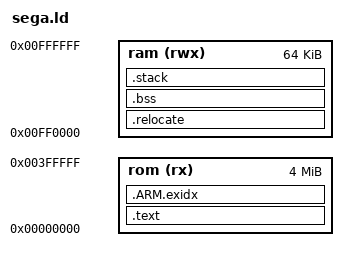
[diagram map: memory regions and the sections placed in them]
/*
 * Sega Genesis Base Project
 *
 * Copyright (c) 2023 Neil Klingensmith
 * neil@cs.luc.edu
 *
 *
 * Permission is hereby granted, free of charge, to any person obtaining a copy
 * of this software and associated documentation files (the "Software"), to deal
 * in the Software without restriction, including without limitation the rights
 * to use, copy, modify, merge, publish, distribute, sublicense, and/or sell
 * copies of the Software, and to permit persons to whom the Software is
 * furnished to do so, subject to the following conditions:
 * 
 * The above copyright notice and this permission notice shall be included in all
 * copies or substantial portions of the Software.
 * 
 * THE SOFTWARE IS PROVIDED "AS IS", WITHOUT WARRANTY OF ANY KIND, EXPRESS OR
 * IMPLIED, INCLUDING BUT NOT LIMITED TO THE WARRANTIES OF MERCHANTABILITY,
 * FITNESS FOR A PARTICULAR PURPOSE AND NONINFRINGEMENT. IN NO EVENT SHALL THE
 * AUTHORS OR COPYRIGHT HOLDERS BE LIABLE FOR ANY CLAIM, DAMAGES OR OTHER
 * LIABILITY, WHETHER IN AN ACTION OF CONTRACT, TORT OR OTHERWISE, ARISING FROM,
 * OUT OF OR IN CONNECTION WITH THE SOFTWARE OR THE USE OR OTHER DEALINGS IN THE
 * SOFTWARE.
 *
 */

STACK_SIZE = DEFINED(STACK_SIZE) ? STACK_SIZE : DEFINED(__stack_size__) ? __stack_size__ : 0x800;

/* Memory Spaces Definitions */
MEMORY
{
  rom      (rx)  : ORIGIN = 0x000000, LENGTH = 0x400000
  ram      (rwx) : ORIGIN = 0xFF0000, LENGTH = 0x010000
}

/* Section Definitions */
SECTIONS
{
    .text :
    {
        . = ALIGN(4);
        _sfixed = .;
        KEEP(*(.vectors .vectors.*))
	KEEP(*(.romheader))
        *(.text .text.* .gnu.linkonce.t.*)
        *(.glue_7t) *(.glue_7)
        *(.rodata .rodata* .gnu.linkonce.r.*)
        *(.ARM.extab* .gnu.linkonce.armextab.*)

        /* Support C constructors, and C destructors in both user code
           and the C library. This also provides support for C++ code. */
        . = ALIGN(4);
        KEEP(*(.init))
        . = ALIGN(4);
        __preinit_array_start = .;
        KEEP (*(.preinit_array))
        __preinit_array_end = .;

        . = ALIGN(4);
        __init_array_start = .;
        KEEP (*(SORT(.init_array.*)))
        KEEP (*(.init_array))
        __init_array_end = .;

        . = ALIGN(4);
        KEEP (*crtbegin.o(.ctors))
        KEEP (*(EXCLUDE_FILE (*crtend.o) .ctors))
        KEEP (*(SORT(.ctors.*)))
        KEEP (*crtend.o(.ctors))

        . = ALIGN(4);
        KEEP(*(.fini))

        . = ALIGN(4);
        __fini_array_start = .;
        KEEP (*(.fini_array))
        KEEP (*(SORT(.fini_array.*)))
        __fini_array_end = .;

        KEEP (*crtbegin.o(.dtors))
        KEEP (*(EXCLUDE_FILE (*crtend.o) .dtors))
        KEEP (*(SORT(.dtors.*)))
        KEEP (*crtend.o(.dtors))

        . = ALIGN(4);
        _efixed = .;            /* End of text section */
    } > rom

    /* .ARM.exidx is sorted, so has to go in its own output section.  */
    PROVIDE_HIDDEN (__exidx_start = .);
    .ARM.exidx :
    {
      *(.ARM.exidx* .gnu.linkonce.armexidx.*)
    } > rom
    PROVIDE_HIDDEN (__exidx_end = .);

    . = ALIGN(4);
    _etext = .;

    .relocate : AT (_etext)
    {
        . = ALIGN(4);
        _srelocate = .;
        *(.ramfunc .ramfunc.*);
        *(.data .data.*);
        . = ALIGN(4);
        _erelocate = .;
    } > ram
    /* .bss section which is used for uninitialized data */
    .bss (NOLOAD) :
    {
        . = ALIGN(4);
        __bss_start__ = .;
        _sbss = . ;
        _szero = .;
        *(.bss .bss.*)
        *(COMMON)
        . = ALIGN(4);
        _ebss = . ;
        _ezero = .;
        __bss_end__ = .;
    } > ram

    /* stack section */
    .stack (NOLOAD):
    {
        . = ALIGN(8);
        _sstack = .;
        . = . + STACK_SIZE;
        . = ALIGN(8);
        _estack = .;
    } > ram

    . = ALIGN(4);
    _end = . ;
}

